# SFR_445.0 register map
Vendor: Texas Instruments
Peripheral module from a debugger description file (folder msp430).
Registers are 16-bit, read-write, no defined reset value unless marked. A register's access mark holds for its fields unless they carry their own. Offsets are as the file gives them; lines under a group give offsets from that group; [hi:lo] are bit positions; {n}, {i} and the like mark numbered series; 'fields as' and 'values as' point back to an identical list; <NAME> marks a mode.

## SFR
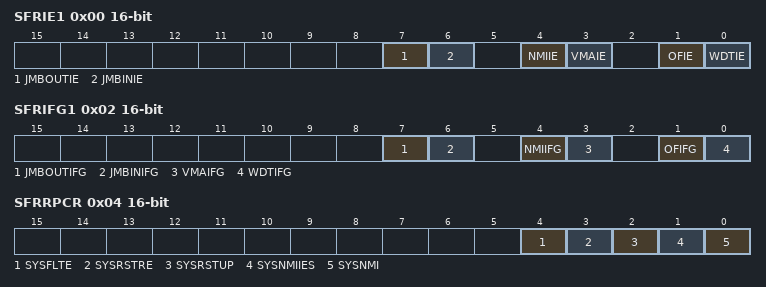
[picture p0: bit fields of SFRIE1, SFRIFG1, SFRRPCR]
0x00 SFRIE1 — Interrupt Enable
  [all] fields
    0=DISABLE (Interrupts disabled); 1=ENABLE (Interrupts enabled)
  [7] JMBOUTIE — JTAG mailbox output interrupt enable
  [6] JMBINIE — JTAG mailbox input interrupt enable
  [4] NMIIE — NMI pin interrupt enable
  [3] VMAIE — Vacant memory access interrupt enable
  [1] OFIE — Oscillator fault interrupt enable
  [0] WDTIE — Watchdog timer interrupt enable
0x02 SFRIFG1 — Interrupt Flag
  [7] JMBOUTIFG — JTAG mailbox output interrupt flag
    0=No interrupt pending. When in 16-bit mode (JMBMODE = 0), this bit is cleared automatically when JMBO0 has been written with a new message to the JTAG module by the CPU. When in 32-bit mode (JMBMODE = 1), this bit is cleared automatically when both JMBO0 and JMBO1 have been written with new messages to the JTAG module by the CPU. This bit is also cleared when the associated vector in SYSUNIV has been read.; 1=Interrupt pending. JMBO registers are ready for new messages. In 16-bit mode (JMBMODE = 0), JMBO0 has been received by the JTAG module and is ready for a new message from the CPU. In 32-bit mode (JMBMODE = 1), JMBO0 and JMBO1 have been received by the JTAG module and are ready for new messages from the CPU.
  [6] JMBINIFG — JTAG mailbox input interrupt flag
    0=No interrupt pending. When in 16-bit mode (JMBMODE = 0), this bit is cleared automatically when JMBI0 is read by the CPU. When in 32-bit mode (JMBMODE = 1), this bit is cleared automatically when both JMBI0 and JMBI1 have been read by the CPU. This bit is also cleared when the associated vector in SYSUNIV has been read; 1=Interrupt pending. A message is waiting in the JMBIN registers. In 16-bit mode (JMBMODE = 0) when JMBI0 has been written by the JTAG module. In 32-bit mode (JMBMODE = 1) when JMBI0 and JMBI1 have been written by the JTAG module.
  [4] NMIIFG — NMI pin interrupt flag
    0=No interrupt pending; 1=Interrupt pending
  [3] VMAIFG — Vacant memory access interrupt flag
    0=No interrupt pending; 1=Interrupt pending
  [1] OFIFG — Oscillator fault interrupt flag
    0=No interrupt pending; 1=Interrupt pending
  [0] WDTIFG — Watchdog timer interrupt flag
    0=No interrupt pending; 1=Interrupt pending
0x04 SFRRPCR — Reset Pin Control
  [4] SYSFLTE — Reset pin filter enable
    0=DISABLED (Digital filter on reset pin is disabled); 1=ENABLED (Digital filter on reset pin is enabled)
  [3] SYSRSTRE — Reset pin resistor enable
    0=DISABLE (Pullup or pulldown resistor at the RST/NMI pin is disabled); 1=ENABLE (Pullup or pulldown resistor at the RST/NMI pin is enabled)
  [2] SYSRSTUP — Reset resistor pin pullup or pulldown
    0=PULLDOWN (Pulldown is selected); 1=PULLUP (Pullup is selected)
  [1] SYSNMIIES — NMI edge select
    0=RISING (NMI on rising edge); 1=FALLING (NMI on falling edge)
  [0] SYSNMI — NMI select
    0=RESET (Reset function); 1=NMI (NMI function)
